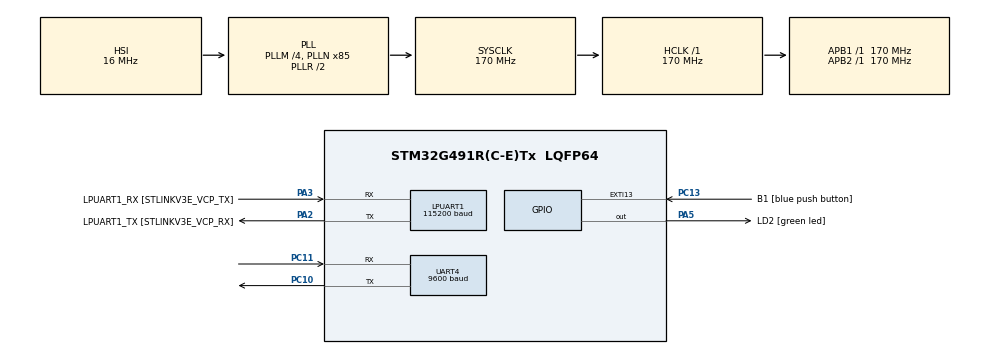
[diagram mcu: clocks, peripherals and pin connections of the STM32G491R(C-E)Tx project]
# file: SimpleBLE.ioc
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Dma.LPUART1_TX.0.Direction=DMA_MEMORY_TO_PERIPH
Dma.LPUART1_TX.0.EventEnable=DISABLE
Dma.LPUART1_TX.0.Instance=DMA1_Channel1
Dma.LPUART1_TX.0.MemDataAlignment=DMA_MDATAALIGN_BYTE
Dma.LPUART1_TX.0.MemInc=DMA_MINC_ENABLE
Dma.LPUART1_TX.0.Mode=DMA_NORMAL
Dma.LPUART1_TX.0.PeriphDataAlignment=DMA_PDATAALIGN_BYTE
Dma.LPUART1_TX.0.PeriphInc=DMA_PINC_DISABLE
Dma.LPUART1_TX.0.Polarity=HAL_DMAMUX_REQ_GEN_RISING
Dma.LPUART1_TX.0.Priority=DMA_PRIORITY_LOW
Dma.LPUART1_TX.0.RequestNumber=1
Dma.LPUART1_TX.0.SignalID=NONE
Dma.LPUART1_TX.0.SyncEnable=DISABLE
Dma.LPUART1_TX.0.SyncPolarity=HAL_DMAMUX_SYNC_NO_EVENT
Dma.LPUART1_TX.0.SyncRequestNumber=1
Dma.LPUART1_TX.0.SyncSignalID=NONE
Dma.Request0=LPUART1_TX
Dma.Request1=UART4_TX
Dma.UART4_TX.1.Direction=DMA_MEMORY_TO_PERIPH
Dma.UART4_TX.1.EventEnable=DISABLE
Dma.UART4_TX.1.Instance=DMA1_Channel2
Dma.UART4_TX.1.MemDataAlignment=DMA_MDATAALIGN_BYTE
Dma.UART4_TX.1.MemInc=DMA_MINC_ENABLE
Dma.UART4_TX.1.Mode=DMA_NORMAL
Dma.UART4_TX.1.PeriphDataAlignment=DMA_PDATAALIGN_BYTE
Dma.UART4_TX.1.PeriphInc=DMA_PINC_DISABLE
Dma.UART4_TX.1.Polarity=HAL_DMAMUX_REQ_GEN_RISING
Dma.UART4_TX.1.Priority=DMA_PRIORITY_LOW
Dma.UART4_TX.1.RequestNumber=1
Dma.UART4_TX.1.SignalID=NONE
Dma.UART4_TX.1.SyncEnable=DISABLE
Dma.UART4_TX.1.SyncPolarity=HAL_DMAMUX_SYNC_NO_EVENT
Dma.UART4_TX.1.SyncRequestNumber=1
Dma.UART4_TX.1.SyncSignalID=NONE
FREERTOS.MEMORY_ALLOCATION=1
FREERTOS.Queues01=resQueue,8,resmsg_t,0,Static,resQueueBuffer,resQueueControlBlock
FREERTOS.Tasks01=comTask,0,512,StartComTask,As weak,NULL,Static,comTaskBuffer,comTaskControlBlock;bleTask,2,256,StartBleTask,As external,NULL,Static,myBleTaskBuffer,myBleTaskControlBlock
LPUART1.BaudRate=115200
LPUART1.WordLength=UART_WORDLENGTH_8B
Mcu.Family=STM32G4
Mcu.Name=STM32G491R(C-E)Tx
Mcu.Package=LQFP64
NVIC.DMA1_Channel1_IRQn=true\:5\:0\:false\:false\:true\:true\:false\:true\:true
NVIC.DMA1_Channel2_IRQn=true\:5\:0\:false\:false\:true\:true\:false\:true\:true
NVIC.EXTI15_10_IRQn=true\:5\:0\:false\:false\:true\:true\:true\:true\:true
NVIC.LPUART1_IRQn=true\:5\:0\:false\:false\:true\:true\:true\:true\:true
NVIC.PriorityGroup=NVIC_PRIORITYGROUP_4
NVIC.TIM7_IRQn=true\:15\:0\:false\:false\:true\:false\:false\:true\:true
NVIC.TimeBase=TIM7_IRQn
NVIC.TimeBaseIP=TIM7
NVIC.UART4_IRQn=true\:5\:0\:false\:false\:true\:true\:true\:true\:true
PA13.GPIO_Label=T_SWDIO
PA13.Mode=Trace_Asynchronous_SW
PA13.Signal=SYS_JTMS-SWDIO
PA14.GPIO_Label=T_SWCLK
PA14.Mode=Trace_Asynchronous_SW
PA14.Signal=SYS_JTCK-SWCLK
PA2.GPIO_Label=LPUART1_TX [STLINKV3E_VCP_RX]
PA2.Mode=Asynchronous
PA2.Signal=LPUART1_TX
PA3.GPIO_Label=LPUART1_RX [STLINKV3E_VCP_TX]
PA3.Mode=Asynchronous
PA3.Signal=LPUART1_RX
PA5.GPIO_Label=LD2 [green led]
PA5.Signal=GPIO_Output
PB3.GPIO_Label=T_SWO
PB3.Mode=Trace_Asynchronous_SW
PB3.Signal=SYS_JTDO-SWO
PC10.Mode=Asynchronous
PC10.Signal=UART4_TX
PC11.Mode=Asynchronous
PC11.Signal=UART4_RX
PC13.GPIO_Label=B1 [blue push button]
PC13.Signal=GPXTI13
PC14-OSC32_IN.Mode=LSE-External-Oscillator
PC14-OSC32_IN.Signal=RCC_OSC32_IN
PC15-OSC32_OUT.Mode=LSE-External-Oscillator
PC15-OSC32_OUT.Signal=RCC_OSC32_OUT
PF0-OSC_IN.Mode=HSE-External-Oscillator
PF0-OSC_IN.Signal=RCC_OSC_IN
PF1-OSC_OUT.Mode=HSE-External-Oscillator
PF1-OSC_OUT.Signal=RCC_OSC_OUT
ProjectManager.HeapSize=0x200
ProjectManager.StackSize=0x400
ProjectManager.TargetToolchain=STM32CubeIDE
RCC.ADC12Freq_Value=170000000
RCC.ADC345Freq_Value=170000000
RCC.AHBFreq_Value=170000000
RCC.APB1Freq_Value=170000000
RCC.APB1TimFreq_Value=170000000
RCC.APB2Freq_Value=170000000
RCC.APB2TimFreq_Value=170000000
RCC.CortexFreq_Value=170000000
RCC.EXTERNAL_CLOCK_VALUE=12288000
RCC.HCLKFreq_Value=170000000
RCC.HSE_VALUE=24000000
RCC.HSI48_VALUE=48000000
RCC.HSI_VALUE=16000000
RCC.PLLM=RCC_PLLM_DIV4
RCC.PLLN=85
RCC.RTCClockSelection=RCC_RTCCLKSOURCE_LSE
RCC.SYSCLKFreq_VALUE=170000000
RCC.SYSCLKSource=RCC_SYSCLKSOURCE_PLLCLK
RCC.USBFreq_Value=48000000
RCC.VCOOutputFreq_Value=340000000
UART4.BaudRate=9600
VP_FREERTOS_VS_CMSIS_V1.Mode=CMSIS_V1
VP_SYS_VS_DBSignals.Mode=DisableDeadBatterySignals
VP_SYS_VS_tim7.Mode=TIM7
board=NUCLEO-G491RE

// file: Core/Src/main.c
/* USER CODE BEGIN Header */
/**
  ******************************************************************************
  * @file           : main.c
  * @brief          : Main program body
  ******************************************************************************
  * @attention
  *
  * Copyright (c) 2024 STMicroelectronics.
  * All rights reserved.
  *
  * This software is licensed under terms that can be found in the LICENSE file
  * in the root directory of this software component.
  * If no LICENSE file comes with this software, it is provided AS-IS.
  *
  ******************************************************************************
  */
/* USER CODE END Header */
#include "main.h"
#include "cmsis_os.h"

/* USER CODE BEGIN Includes */
#include "../../SimpleBle/resmsg.h"
/* USER CODE END Includes */

UART_HandleTypeDef hlpuart1;
UART_HandleTypeDef huart4;
DMA_HandleTypeDef hdma_lpuart1_tx;
DMA_HandleTypeDef hdma_uart4_tx;

osThreadId comTaskHandle;
uint32_t comTaskBuffer[ 512 ];
osStaticThreadDef_t comTaskControlBlock;
osThreadId bleTaskHandle;
uint32_t myBleTaskBuffer[ 256 ];
osStaticThreadDef_t myBleTaskControlBlock;
osMessageQId resQueueHandle;
uint8_t resQueueBuffer[ 8 * sizeof( resmsg_t ) ];
osStaticMessageQDef_t resQueueControlBlock;

void SystemClock_Config(void);
static void MX_GPIO_Init(void);
static void MX_DMA_Init(void);
static void MX_LPUART1_UART_Init(void);
static void MX_UART4_Init(void);
void StartComTask(void const * argument);
extern void StartBleTask(void const * argument);

int main(void)
{

  /* MCU Configuration--------------------------------------------------------*/

  /* Reset of all peripherals, Initializes the Flash interface and the Systick. */
  HAL_Init();

  /* Configure the system clock */
  SystemClock_Config();

  /* Initialize all configured peripherals */
  MX_GPIO_Init();
  MX_DMA_Init();
  MX_LPUART1_UART_Init();
  MX_UART4_Init();

  /* Create the queue(s) */
  /* definition and creation of resQueue */
  osMessageQStaticDef(resQueue, 8, resmsg_t, resQueueBuffer, &resQueueControlBlock);
  resQueueHandle = osMessageCreate(osMessageQ(resQueue), NULL);

  /* Create the thread(s) */
  /* definition and creation of comTask */
  osThreadStaticDef(comTask, StartComTask, osPriorityNormal, 0, 512, comTaskBuffer, &comTaskControlBlock);
  comTaskHandle = osThreadCreate(osThread(comTask), NULL);

  /* definition and creation of bleTask */
  osThreadStaticDef(bleTask, StartBleTask, osPriorityHigh, 0, 256, myBleTaskBuffer, &myBleTaskControlBlock);
  bleTaskHandle = osThreadCreate(osThread(bleTask), NULL);

  /* Start scheduler */
  osKernelStart();

  /* We should never get here as control is now taken by the scheduler */
  /* Infinite loop */
  while (1)
  {

  }
}

void SystemClock_Config(void)
{
  RCC_OscInitTypeDef RCC_OscInitStruct = {0};
  RCC_ClkInitTypeDef RCC_ClkInitStruct = {0};

  /** Configure the main internal regulator output voltage
  */
  HAL_PWREx_ControlVoltageScaling(PWR_REGULATOR_VOLTAGE_SCALE1_BOOST);

  /** Initializes the RCC Oscillators according to the specified parameters
  * in the RCC_OscInitTypeDef structure.
  */
  RCC_OscInitStruct.OscillatorType = RCC_OSCILLATORTYPE_HSI;
  RCC_OscInitStruct.HSIState = RCC_HSI_ON;
  RCC_OscInitStruct.HSICalibrationValue = RCC_HSICALIBRATION_DEFAULT;
  RCC_OscInitStruct.PLL.PLLState = RCC_PLL_ON;
  RCC_OscInitStruct.PLL.PLLSource = RCC_PLLSOURCE_HSI;
  RCC_OscInitStruct.PLL.PLLM = RCC_PLLM_DIV4;
  RCC_OscInitStruct.PLL.PLLN = 85;
  RCC_OscInitStruct.PLL.PLLP = RCC_PLLP_DIV2;
  RCC_OscInitStruct.PLL.PLLQ = RCC_PLLQ_DIV2;
  RCC_OscInitStruct.PLL.PLLR = RCC_PLLR_DIV2;
  if (HAL_RCC_OscConfig(&RCC_OscInitStruct) != HAL_OK)
  {
    Error_Handler();
  }

  /** Initializes the CPU, AHB and APB buses clocks
  */
  RCC_ClkInitStruct.ClockType = RCC_CLOCKTYPE_HCLK|RCC_CLOCKTYPE_SYSCLK
                              |RCC_CLOCKTYPE_PCLK1|RCC_CLOCKTYPE_PCLK2;
  RCC_ClkInitStruct.SYSCLKSource = RCC_SYSCLKSOURCE_PLLCLK;
  RCC_ClkInitStruct.AHBCLKDivider = RCC_SYSCLK_DIV1;
  RCC_ClkInitStruct.APB1CLKDivider = RCC_HCLK_DIV1;
  RCC_ClkInitStruct.APB2CLKDivider = RCC_HCLK_DIV1;

  if (HAL_RCC_ClockConfig(&RCC_ClkInitStruct, FLASH_LATENCY_4) != HAL_OK)
  {
    Error_Handler();
  }
}

static void MX_LPUART1_UART_Init(void)
{

  hlpuart1.Instance = LPUART1;
  hlpuart1.Init.BaudRate = 115200;
  hlpuart1.Init.WordLength = UART_WORDLENGTH_8B;
  hlpuart1.Init.StopBits = UART_STOPBITS_1;
  hlpuart1.Init.Parity = UART_PARITY_NONE;
  hlpuart1.Init.Mode = UART_MODE_TX_RX;
  hlpuart1.Init.HwFlowCtl = UART_HWCONTROL_NONE;
  hlpuart1.Init.OneBitSampling = UART_ONE_BIT_SAMPLE_DISABLE;
  hlpuart1.Init.ClockPrescaler = UART_PRESCALER_DIV1;
  hlpuart1.AdvancedInit.AdvFeatureInit = UART_ADVFEATURE_NO_INIT;
  if (HAL_UART_Init(&hlpuart1) != HAL_OK)
  {
    Error_Handler();
  }
  if (HAL_UARTEx_SetTxFifoThreshold(&hlpuart1, UART_TXFIFO_THRESHOLD_1_8) != HAL_OK)
  {
    Error_Handler();
  }
  if (HAL_UARTEx_SetRxFifoThreshold(&hlpuart1, UART_RXFIFO_THRESHOLD_1_8) != HAL_OK)
  {
    Error_Handler();
  }
  if (HAL_UARTEx_DisableFifoMode(&hlpuart1) != HAL_OK)
  {
    Error_Handler();
  }

}

static void MX_UART4_Init(void)
{

  huart4.Instance = UART4;
  huart4.Init.BaudRate = 9600;
  huart4.Init.WordLength = UART_WORDLENGTH_8B;
  huart4.Init.StopBits = UART_STOPBITS_1;
  huart4.Init.Parity = UART_PARITY_NONE;
  huart4.Init.Mode = UART_MODE_TX_RX;
  huart4.Init.HwFlowCtl = UART_HWCONTROL_NONE;
  huart4.Init.OverSampling = UART_OVERSAMPLING_16;
  huart4.Init.OneBitSampling = UART_ONE_BIT_SAMPLE_DISABLE;
  huart4.Init.ClockPrescaler = UART_PRESCALER_DIV1;
  huart4.AdvancedInit.AdvFeatureInit = UART_ADVFEATURE_NO_INIT;
  if (HAL_UART_Init(&huart4) != HAL_OK)
  {
    Error_Handler();
  }
  if (HAL_UARTEx_SetTxFifoThreshold(&huart4, UART_TXFIFO_THRESHOLD_1_8) != HAL_OK)
  {
    Error_Handler();
  }
  if (HAL_UARTEx_SetRxFifoThreshold(&huart4, UART_RXFIFO_THRESHOLD_1_8) != HAL_OK)
  {
    Error_Handler();
  }
  if (HAL_UARTEx_DisableFifoMode(&huart4) != HAL_OK)
  {
    Error_Handler();
  }

}

static void MX_DMA_Init(void)
{

  /* DMA controller clock enable */
  __HAL_RCC_DMAMUX1_CLK_ENABLE();
  __HAL_RCC_DMA1_CLK_ENABLE();

  /* DMA interrupt init */
  /* DMA1_Channel1_IRQn interrupt configuration */
  HAL_NVIC_SetPriority(DMA1_Channel1_IRQn, 5, 0);
  HAL_NVIC_EnableIRQ(DMA1_Channel1_IRQn);
  /* DMA1_Channel2_IRQn interrupt configuration */
  HAL_NVIC_SetPriority(DMA1_Channel2_IRQn, 5, 0);
  HAL_NVIC_EnableIRQ(DMA1_Channel2_IRQn);

}

static void MX_GPIO_Init(void)
{
  GPIO_InitTypeDef GPIO_InitStruct = {0};

  /* GPIO Ports Clock Enable */
  __HAL_RCC_GPIOC_CLK_ENABLE();
  __HAL_RCC_GPIOF_CLK_ENABLE();
  __HAL_RCC_GPIOA_CLK_ENABLE();
  __HAL_RCC_GPIOB_CLK_ENABLE();

  /*Configure GPIO pin Output Level */
  HAL_GPIO_WritePin(LD2_GPIO_Port, LD2_Pin, GPIO_PIN_RESET);

  /*Configure GPIO pin : B1_Pin */
  GPIO_InitStruct.Pin = B1_Pin;
  GPIO_InitStruct.Mode = GPIO_MODE_IT_RISING;
  GPIO_InitStruct.Pull = GPIO_NOPULL;
  HAL_GPIO_Init(B1_GPIO_Port, &GPIO_InitStruct);

  /*Configure GPIO pin : LD2_Pin */
  GPIO_InitStruct.Pin = LD2_Pin;
  GPIO_InitStruct.Mode = GPIO_MODE_OUTPUT_PP;
  GPIO_InitStruct.Pull = GPIO_NOPULL;
  GPIO_InitStruct.Speed = GPIO_SPEED_FREQ_LOW;
  HAL_GPIO_Init(LD2_GPIO_Port, &GPIO_InitStruct);

  /* EXTI interrupt init*/
  HAL_NVIC_SetPriority(EXTI15_10_IRQn, 5, 0);
  HAL_NVIC_EnableIRQ(EXTI15_10_IRQn);

}

__weak void StartComTask(void const * argument)
{
  for(;;)
  {
    osDelay(1);
  }
}

void HAL_TIM_PeriodElapsedCallback(TIM_HandleTypeDef *htim)
{
  if (htim->Instance == TIM7) {
    HAL_IncTick();
  }
}

void Error_Handler(void)
{
  __disable_irq();
  while (1)
  {
  }
}

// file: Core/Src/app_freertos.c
/* USER CODE BEGIN Header */
/**
  ******************************************************************************
  * File Name          : app_freertos.c
  * Description        : Code for freertos applications
  ******************************************************************************
  * @attention
  *
  * Copyright (c) 2024 STMicroelectronics.
  * All rights reserved.
  *
  * This software is licensed under terms that can be found in the LICENSE file
  * in the root directory of this software component.
  * If no LICENSE file comes with this software, it is provided AS-IS.
  *
  ******************************************************************************
  */
/* USER CODE END Header */

#include "FreeRTOS.h"
#include "task.h"
#include "main.h"

/* GetIdleTaskMemory prototype (linked to static allocation support) */
void vApplicationGetIdleTaskMemory( StaticTask_t **ppxIdleTaskTCBBuffer, StackType_t **ppxIdleTaskStackBuffer, uint32_t *pulIdleTaskStackSize );

/* USER CODE BEGIN GET_IDLE_TASK_MEMORY */
static StaticTask_t xIdleTaskTCBBuffer;
static StackType_t xIdleStack[configMINIMAL_STACK_SIZE];

void vApplicationGetIdleTaskMemory( StaticTask_t **ppxIdleTaskTCBBuffer, StackType_t **ppxIdleTaskStackBuffer, uint32_t *pulIdleTaskStackSize )
{
  *ppxIdleTaskTCBBuffer = &xIdleTaskTCBBuffer;
  *ppxIdleTaskStackBuffer = &xIdleStack[0];
  *pulIdleTaskStackSize = configMINIMAL_STACK_SIZE;
  /* place for user code */
}
/* USER CODE END GET_IDLE_TASK_MEMORY */
